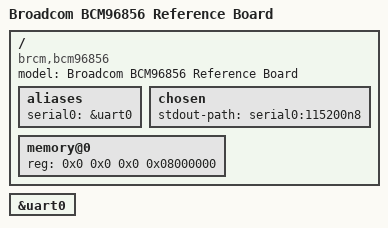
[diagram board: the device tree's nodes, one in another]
// SPDX-License-Identifier: (GPL-2.0+ OR MIT)
/*
 * Copyright 2022 Broadcom Ltd.
 */

/dts-v1/;

#include "bcm6856.dtsi"

/ {
	model = "Broadcom BCM96856 Reference Board";
	compatible = "brcm,bcm96856", "brcm,bcm6856", "brcm,bcmbca";

	aliases {
		serial0 = &uart0;
	};

	chosen {
		stdout-path = "serial0:115200n8";
	};

	memory@0 {
		device_type = "memory";
		reg = <0x0 0x0 0x0 0x08000000>;
	};
};

&uart0 {
	status = "okay";
};
